# CYBLE_224116_01 register map
File version: 0.1
PSoC 4200 BLE
Registers are 32-bit, read-write, no defined reset value unless marked. A register's access mark holds for its fields unless they carry their own. Offsets are from the block's base; lines under a group give offsets from that group; [hi:lo] are bit positions; {n}, {i} and the like mark numbered series; 'fields as' and 'values as' point back to an identical list; <NAME> marks a mode.

## Memory map
0x00000000 ScreenCounter
0x00000000 SWTimer
0x00000000 UART2 — UART
0x00000000 DMAC — DMAC Registers
0x00000000 BLETimer
0x00000000 MessageTimer
0x00000000 I2C — Serial Communication Block
0x00000000 ModbusUART — Serial Communication Block

## ScreenCounter
Base 0x00000000
0x40200148 COUNTER — Current counter value
0x4020014C CC — Compare / capture value
0x40200150 CC_BUF — Compare / capture buffer value
0x40200154 PERIOD — Period value
0x40200158 PERIOD_BUF — Period buffer value

## SWTimer
Base 0x00000000
0x40200188 COUNTER — Current counter value
0x4020018C CC — Compare / capture value
0x40200190 CC_BUF — Compare / capture buffer value
0x40200194 PERIOD — Period value
0x40200198 PERIOD_BUF — Period buffer value

## UART2 — UART
Base 0x00000000
0x400F0021 RX_UART2_RX_ADDRESS1 8-bit — RX Address1 Register
0x400F0031 RX_UART2_RX_ADDRESS2 8-bit — RX Address2 Register
0x400F0041 RX_UART2_RX_DATA 8-bit — RX Data Register
0x400F0042 TX_UART2_TX_DATA 8-bit — TX Data Register
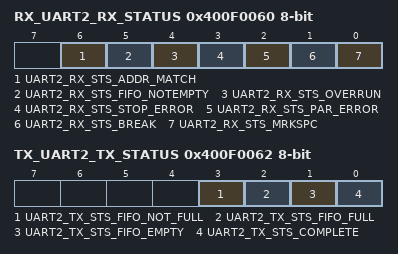
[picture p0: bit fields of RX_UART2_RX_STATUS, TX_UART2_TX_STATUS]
0x400F0060 RX_UART2_RX_STATUS 8-bit — RX status register
  [6] UART2_RX_STS_ADDR_MATCH ro, [5] UART2_RX_STS_FIFO_NOTEMPTY ro, [4] UART2_RX_STS_OVERRUN ro, [3] UART2_RX_STS_STOP_ERROR ro, [2] UART2_RX_STS_PAR_ERROR ro, [1] UART2_RX_STS_BREAK ro, [0] UART2_RX_STS_MRKSPC ro
0x400F0062 TX_UART2_TX_STATUS 8-bit — TX status register
  [3] UART2_TX_STS_FIFO_NOT_FULL ro, [2] UART2_TX_STS_FIFO_FULL ro, [1] UART2_TX_STS_FIFO_EMPTY ro, [0] UART2_TX_STS_COMPLETE ro

## BLETimer
Base 0x00000000
0x40200108 COUNTER — Current counter value
0x4020010C CC — Compare / capture value
0x40200110 CC_BUF — Compare / capture buffer value
0x40200114 PERIOD — Period value
0x40200118 PERIOD_BUF — Period buffer value

## MessageTimer
Base 0x00000000
0x402001C8 COUNTER — Current counter value
0x402001CC CC — Compare / capture value
0x402001D0 CC_BUF — Compare / capture buffer value
0x402001D4 PERIOD — Period value
0x402001D8 PERIOD_BUF — Period buffer value
